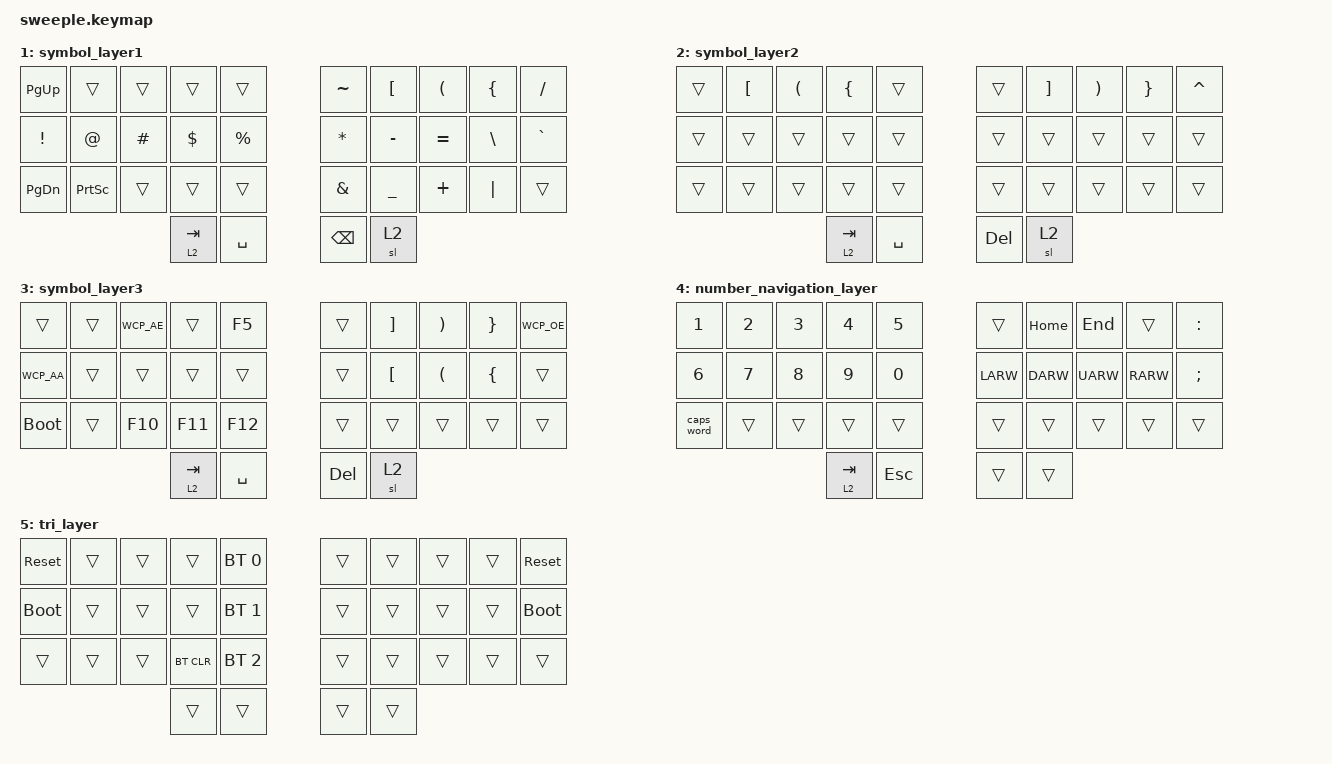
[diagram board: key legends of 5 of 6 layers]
// Copyright (c) 2022 The ZMK Contributors
// SPDX-License-Identifier: MIT

#include <behaviors.dtsi>
#include <dt-bindings/zmk/keys.h>
#include <dt-bindings/zmk/bt.h>

// Home row mods macro
#define HRML(k1,k2,k3,k4) &ht LSHFT k1 &ht LALT k2   &ht LCTRL k3 &ht LGUI k4
#define HRMR(k1,k2,k3,k4) &ht RGUI k1  &ht RCTRL k2  &ht RALT k3  &ht RSHFT k4

/ {
    macros {
        WCP_OE: WCP_OE {
            label = "WCP_OE";
            compatible = "zmk,behavior-macro";
            #binding-cells = <0>;
            bindings = <&macro_press &kp RALT>, <&macro_tap &kp O &kp FSLH>, <&macro_release &kp RALT>;
        };
        WCP_AA: WCP_AA {
            label = "WCP_AA";
            compatible = "zmk,behavior-macro";
            #binding-cells = <0>;
            bindings = <&macro_press &kp RALT>, <&macro_tap &kp O &kp A>, <&macro_release &kp RALT>;
        };
        WCP_AE: WCP_AE {
            label = "WCP_AE";
            compatible = "zmk,behavior-macro";
            #binding-cells = <0>;
            bindings = <&macro_press &kp RALT>, <&macro_tap &kp A &kp E>, <&macro_release &kp RALT>;
        };
        tmux_cb: tmux_cb{
            label = "tmux_cb";
            compatible = "zmk,behavior-macro";
            #binding-cells = <0>;
            bindings = <&macro_press &kp LCTRL>, <&macro_tap &kp B>, <&macro_release &kp LCTRL>;
        };
  };

    behaviors {
        htl: hold_tap_leader {
            label = "leader_hold_tap";
            compatible = "zmk,behavior-hold-tap";
            #binding-cells = <2>; 
            flavor = "tap-preferred"; 
            tapping-term-ms = <200>; 
            bindings = <&mo>, <&sl>; 
        };

        ht: hold_tap {
            label = "hold_tap";
            compatible = "zmk,behavior-hold-tap";
            #binding-cells = <2>;
            flavor = "tap-preferred";
            tapping-term-ms = <190>;
            quick-tap-ms = <100>;
            global-quick-tap;
            bindings = <&kp>, <&kp>;
        };
    };

    conditional_layers {
        compatible = "zmk,conditional-layers";
        tri_layer {
            if-layers = <4 2>;
            then-layer = <5>;
        };
    };


    keymap {
        compatible = "zmk,keymap";
        default_layer {
            bindings = <
        //╭──────────┬──────────┬──────────┬──────────┬──────────╮   ╭──────────┬──────────┬──────────┬──────────┬──────────╮
        //│   Q      │  W       │  E       │  R       │  T       │   │  Y       │  U       │  I       │  O       │  P       │
            &kp Q      &kp W      &kp E      &kp R      &kp T          &kp Y      &kp U      &kp I      &kp O      &kp P
        //├──────────┼──────────┼──────────┼──────────┼──────────┤   ├──────────┼──────────┼──────────┼──────────┼──────────┤
        //│  A       │  S       │  D       │  F       │  G       │   │  H       │  J       │  K       │  L       │ ' "      │
            HRML(A,        S,         D,         F)     &kp G          &kp H      HRMR(J,        K,         L,        SQT)
        //├──────────┼──────────┼──────────┼──────────┼──────────┤   ├──────────┼──────────┼──────────┼──────────┼──────────┤
        //│  Z       │  X       │  C       │  V       │  B       │   │  N       │  M       │ , <      │ . >      │ ENTER    │
            &kp Z      &kp X      &kp C      &kp V      &kp B          &kp N      &kp M      &kp COMMA  &kp DOT    &kp ENTER
        //╰──────────┴──────────┴──────────┼──────────┼──────────┤   ├──────────┼──────────┼──────────┴──────────┴──────────╯
                                            &lt 3 TAB   &kp SPACE      &kp BSPC  &htl 4 1 
        //                                   ╰──────────┴──────────╯   ╰──────────┴──────────╯
            >;
        };
        symbol_layer1 {
            bindings = <
        //╭──────────┬──────────┬──────────┬──────────┬──────────╮   ╭──────────┬──────────┬──────────┬──────────┬──────────╮
        //│  PAGE_UP │          │          │          │          │   │ ~        │  [       │  (       │ {        │    / ?   │
            &kp PG_UP  &trans     &trans     &trans     &trans         &kp TILDE  &kp LBKT  &kp LPAR    &kp LBRC   &kp FSLH      
        //├──────────┼──────────┼──────────┼──────────┼──────────┤   ├──────────┼──────────┼──────────┼──────────┼──────────┤
        //│  !       │  @       │  #       │  $       │  %       │   │  *       │  -       │  =       │  \       │  `       │
            &kp EXCL   &kp AT     &kp HASH   &kp DLLR   &kp PRCNT      &kp ASTRK  &kp MINUS  &kp EQUAL  &kp BSLH   &kp GRAVE
        //├──────────┼──────────┼──────────┼──────────┼──────────┤   ├──────────┼──────────┼──────────┼──────────┼──────────┤
        //│ PAGE_DN  │ PRINT_SCR│          │          │          │   │  &       │  _       │  +       │  │       │          │
            &kp PG_DN  &kp PSCRN  &trans     &trans     &trans         &kp AMPS   &kp UNDER  &kp PLUS   &kp PIPE   &trans
        //╰──────────┴──────────┴──────────┼──────────┼──────────┤   ├──────────┼──────────┼──────────┴──────────┴──────────╯
                                            &lt 2 TAB   &kp SPACE      &kp BSPC  &sl 2
        //                                 ╰──────────┴──────────╯   ╰──────────┴──────────╯
            >;
        };
        symbol_layer2 {
            bindings = <
        //╭──────────┬──────────┬──────────┬──────────┬──────────╮   ╭──────────┬──────────┬──────────┬──────────┬──────────╮
        //│          │          │          │          │          │   │          │          │          │          │          │
            &trans     &kp LBKT   &kp LPAR   &kp LBRC   &trans          &trans    &kp RBKT    &kp RPAR  &kp RBRC   &kp CARET
        //┼──────────┼──────────┼──────────┼──────────┼──────────┤   ├──────────┼──────────┼──────────┼──────────┼──────────┤
        //│          │          │          │          │          │   │          │          │          │          │          │
            &trans     &trans     &trans     &trans     &trans          &trans    &trans      &trans     &trans    &trans
        //┼──────────┼──────────┼──────────┼──────────┼──────────┤   ┼──────────┼──────────┼──────────┼──────────┼──────────┤
        //│          │          │          │          │          │   │          │          │          |          │          |
            &trans     &trans     &trans     &trans     &trans          &trans    &trans      &trans     &trans    &trans
        //╰──────────┴──────────┴──────────┼──────────┼──────────┤   ├──────────┼──────────┼──────────┴──────────┴──────────╯
                                            &lt 2 TAB   &kp SPACE      &kp DEL    &sl 2
        //                                 ╰──────────┴──────────╯   ╰──────────┴──────────╯
            >;
        }; 
        symbol_layer3 {
            bindings = <
        //╭──────────┬──────────┬──────────┬──────────┬──────────╮   ╭──────────┬──────────┬──────────┬──────────┬──────────╮
        //│          │          │          │          │          │   │          │          │          │          │          │
            &trans      &trans    &WCP_AE    &trans     &kp F5         &trans     &kp RBKT    &kp RPAR   &kp RBRC  &WCP_OE
        //┼──────────┼──────────┼──────────┼──────────┼──────────┤   ├──────────┼──────────┼──────────┼──────────┼──────────┤
        //│          │          │          │          │          │   │          │          │          │          │          │
            &WCP_AA     &trans    &trans     &trans     &trans         &trans     &kp LBKT   &kp LPAR   &kp LBRC   &trans
        //┼──────────┼──────────┼──────────┼──────────┼──────────┤   ┼──────────┼──────────┼──────────┼──────────┼──────────┤
        //│          │          │          │          │          │   │          │          │          |          │          |
            &bootloader &trans    &kp F10    &kp F11    &kp F12        &trans     &trans      &trans    &trans     &trans
        //╰──────────┴──────────┴──────────┼──────────┼──────────┤   ├──────────┼──────────┼──────────┴──────────┴──────────╯
                                            &lt 2 TAB   &kp SPACE      &kp DEL    &sl 2
        //                                 ╰──────────┴──────────╯   ╰──────────┴──────────╯
            >;
        };
        number_navigation_layer {
            bindings = <
        //╭──────────┬──────────┬──────────┬──────────┬──────────╮   ╭──────────┬──────────┬──────────┬──────────┬──────────╮
        //│  1       │  2       │  3       │  4       │  5       │   │          │  HOME    │  END     │          │  :       │
             &kp N1    &kp N2     &kp N3     &kp N4     &kp N5         &trans     &kp HOME   &kp END     &trans    &kp COLON
        //├──────────┼──────────┼──────────┼──────────┼──────────┤   ├──────────┼──────────┼──────────┼──────────┼──────────┤
        // │   6      │  7       │  8       │  9       │  0       │   │  LEFT    │  DOWN    │  UP      │  RIGHT      ;      │
            &kp N6     &kp N7     &kp N8     &kp N9     &kp N0         &kp LARW   &kp DARW   &kp UARW    &kp RARW  &kp SEMI
        //├──────────┼──────────┼──────────┼──────────┼──────────┤   ├──────────┼──────────┼──────────┼──────────┼──────────┤
        //│ CAPS     │          │          │          │          │   │          │          │          │          │          │
           &caps_word  &trans     &trans     &trans     &trans         &trans     &trans     &trans     &trans     &trans
        //╰──────────┴──────────┴──────────┼──────────┼──────────┤   ├──────────┼──────────┼──────────┴──────────┴──────────╯
                                             &lt 2 TAB  &kp ESC        &trans     &trans
        //                                 ╰──────────┴──────────╯   ╰──────────┴──────────╯
            >;
        };
        
        tri_layer {
            bindings = <
        //╭──────────┬──────────┬──────────┬──────────┬──────────╮   ╭──────────┬──────────┬──────────┬──────────┬──────────╮
        //│ RESET    │          │          │          │PROFILE 0 │   │          │          │          │          │  RESET   │
           &sys_reset  &trans     &trans     &trans    &bt BT_SEL 0    &trans     &trans     &trans     &trans    &sys_reset
        //├──────────┼──────────┼──────────┼──────────┼──────────┤   ├──────────┼──────────┼──────────┼──────────┼──────────┤
        //│BOOTLOADER│          │          │          │PROFILE 1 │   │          │          │          │          │BOOTLOADER│
           &bootloader &trans     &trans     &trans    &bt BT_SEL 1    &trans     &trans     &trans     &trans    &bootloader
        //├──────────┼──────────┼──────────┼──────────┼──────────┤   ├──────────┼──────────┼──────────┼──────────┼──────────┤
        //│          │          │          │ CLEAR BT │PROFILE 2 │   │          │          │          │          │          │
            &trans     &trans     &trans    &bt BT_CLR &bt BT_SEL 2    &trans     &trans     &trans     &trans     &trans
        //╰──────────┴──────────┴──────────┼──────────┼──────────┤   ├──────────┼──────────┼──────────┴──────────┴──────────╯
                                            &trans     &trans         &trans     &trans
        //                                 ╰──────────┴──────────╯   ╰──────────┴──────────╯
            >;
        };
    };
};
